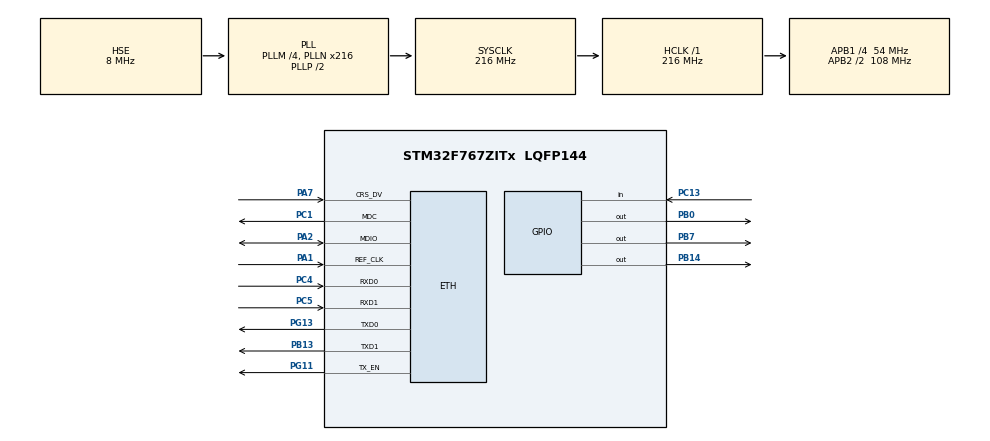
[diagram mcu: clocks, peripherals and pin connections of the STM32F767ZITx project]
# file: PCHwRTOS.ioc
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CORTEX_M7.ART_ACCLERATOR_ENABLE=0
CORTEX_M7.CPU_ICache=Disabled
CORTEX_M7.PREFETCH_ENABLE=0
ETH.MACAddr=44\:84\:23\:84\:44\:77
ETH.MediaInterface=ETH_MEDIA_INTERFACE_RMII
ETH.PHY_BCR=0x00
ETH.PhyAddress=0
LWIP.GATEWAY_ADDRESS=192.168.000.001
LWIP.IP_ADDRESS=192.168.000.211
LWIP.LWIP_DHCP=1
LWIP.LWIP_DNS=1
LWIP.NETMASK_ADDRESS=255.255.255.000
LWIP.Version=v2.0.0_Cube
Mcu.Family=STM32F7
Mcu.Name=STM32F767ZITx
Mcu.Package=LQFP144
NVIC.PriorityGroup=NVIC_PRIORITYGROUP_4
PA1.GPIO_PuPd=GPIO_PULLUP
PA1.Mode=RMII
PA1.Signal=ETH_REF_CLK
PA13.Mode=Serial_Wire
PA13.Signal=SYS_JTMS-SWDIO
PA14.Mode=Serial_Wire
PA14.Signal=SYS_JTCK-SWCLK
PA2.GPIO_PuPd=GPIO_PULLUP
PA2.Mode=RMII
PA2.Signal=ETH_MDIO
PA7.GPIO_PuPd=GPIO_PULLUP
PA7.Mode=RMII
PA7.Signal=ETH_CRS_DV
PB0.Signal=GPIO_Output
PB13.GPIO_PuPd=GPIO_PULLUP
PB13.Mode=RMII
PB13.Signal=ETH_TXD1
PB14.Signal=GPIO_Output
PB7.Signal=GPIO_Output
PC1.GPIO_PuPd=GPIO_PULLUP
PC1.Mode=RMII
PC1.Signal=ETH_MDC
PC13.Signal=GPIO_Input
PC4.GPIO_PuPd=GPIO_PULLUP
PC4.Mode=RMII
PC4.Signal=ETH_RXD0
PC5.GPIO_PuPd=GPIO_PULLUP
PC5.Mode=RMII
PC5.Signal=ETH_RXD1
PG11.GPIO_PuPd=GPIO_PULLUP
PG11.Mode=RMII
PG11.Signal=ETH_TX_EN
PG13.GPIO_PuPd=GPIO_PULLUP
PG13.Mode=RMII
PG13.Signal=ETH_TXD0
PH0/OSC_IN.Mode=HSE-External-Clock-Source
PH0/OSC_IN.Signal=RCC_OSC_IN
PH1/OSC_OUT.Mode=HSE-External-Clock-Source
PH1/OSC_OUT.Signal=RCC_OSC_OUT
ProjectManager.HeapSize=0x2000
ProjectManager.StackSize=0x4000
ProjectManager.TargetToolchain=MDK-ARM V5
RCC.48MHZClocksFreq_Value=24000000
RCC.AHBFreq_Value=216000000
RCC.APB1CLKDivider=RCC_HCLK_DIV4
RCC.APB1Freq_Value=54000000
RCC.APB1TimFreq_Value=108000000
RCC.APB2CLKDivider=RCC_HCLK_DIV2
RCC.APB2Freq_Value=108000000
RCC.APB2TimFreq_Value=216000000
RCC.CortexFreq_Value=216000000
RCC.HCLKFreq_Value=216000000
RCC.HSE_VALUE=8000000
RCC.HSI_VALUE=16000000
RCC.LSE_VALUE=32768
RCC.PLLM=4
RCC.PLLMUL=RCC_PLL_MUL9
RCC.PLLN=216
RCC.PLLSourceVirtual=RCC_PLLSOURCE_HSE
RCC.PRESCALERUSB=RCC_USBCLKSOURCE_PLL_DIV1_5
RCC.SYSCLKFreq_VALUE=216000000
RCC.SYSCLKSource=RCC_SYSCLKSOURCE_PLLCLK
RCC.SYSCLKSourceVirtual=RCC_SYSCLKSOURCE_PLLCLK
RCC.USBFreq_Value=216000000
RCC.VCOOutputFreq_Value=432000000
VP_LWIP_VS_Enabled.Mode=Enabled
board=NUCLEO-F767ZI

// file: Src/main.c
/**
  ******************************************************************************
  * File Name          : main.c
  * Description        : Main program body
  ******************************************************************************
  * This notice applies to any and all portions of this file
  * that are not between comment pairs USER CODE BEGIN and
  * USER CODE END. Other portions of this file, whether
  * inserted by the user or by software development tools
  * are owned by their respective copyright owners.
  *
  * Copyright (c) 2018 STMicroelectronics International N.V.
  * All rights reserved.
  *
  * Redistribution and use in source and binary forms, with or without
  * modification, are permitted, provided that the following conditions are met:
  *
  * 1. Redistribution of source code must retain the above copyright notice,
  *    this list of conditions and the following disclaimer.
  * 2. Redistributions in binary form must reproduce the above copyright notice,
  *    this list of conditions and the following disclaimer in the documentation
  *    and/or other materials provided with the distribution.
  * 3. Neither the name of STMicroelectronics nor the names of other
  *    contributors to this software may be used to endorse or promote products
  *    derived from this software without specific written permission.
  * 4. This software, including modifications and/or derivative works of this
  *    software, must execute solely and exclusively on microcontroller or
  *    microprocessor devices manufactured by or for STMicroelectronics.
  * 5. Redistribution and use of this software other than as permitted under
  *    this license is void and will automatically terminate your rights under
  *    this license.
  *
  * THIS SOFTWARE IS PROVIDED BY STMICROELECTRONICS AND CONTRIBUTORS "AS IS"
  * AND ANY EXPRESS, IMPLIED OR STATUTORY WARRANTIES, INCLUDING, BUT NOT
  * LIMITED TO, THE IMPLIED WARRANTIES OF MERCHANTABILITY, FITNESS FOR A
  * PARTICULAR PURPOSE AND NON-INFRINGEMENT OF THIRD PARTY INTELLECTUAL PROPERTY
  * RIGHTS ARE DISCLAIMED TO THE FULLEST EXTENT PERMITTED BY LAW. IN NO EVENT
  * SHALL STMICROELECTRONICS OR CONTRIBUTORS BE LIABLE FOR ANY DIRECT, INDIRECT,
  * INCIDENTAL, SPECIAL, EXEMPLARY, OR CONSEQUENTIAL DAMAGES (INCLUDING, BUT NOT
  * LIMITED TO, PROCUREMENT OF SUBSTITUTE GOODS OR SERVICES; LOSS OF USE, DATA,
  * OR PROFITS; OR BUSINESS INTERRUPTION) HOWEVER CAUSED AND ON ANY THEORY OF
  * LIABILITY, WHETHER IN CONTRACT, STRICT LIABILITY, OR TORT (INCLUDING
  * NEGLIGENCE OR OTHERWISE) ARISING IN ANY WAY OUT OF THE USE OF THIS SOFTWARE,
  * EVEN IF ADVISED OF THE POSSIBILITY OF SUCH DAMAGE.
  *
  ******************************************************************************
  */

#include "main.h"
#include "stm32f7xx_hal.h"
#include "lwip.h"

/* USER CODE BEGIN Includes */
#include "net.h"
/* USER CODE END Includes */

/* USER CODE BEGIN PV */
/* Private variables ---------------------------------------------------------*/

/* USER CODE END PV */

void SystemClock_Config(void);
static void MX_GPIO_Init(void);

/* USER CODE BEGIN PFP */
/* Private function prototypes -----------------------------------------------*/

/* USER CODE END PFP */

/* USER CODE BEGIN 0 */
extern struct netif gnetif;
/* USER CODE END 0 */

int main(void)
{

  /* MCU Configuration----------------------------------------------------------*/

  /* Reset of all peripherals, Initializes the Flash interface and the Systick. */
  HAL_Init();

  /* Configure the system clock */
  SystemClock_Config();

  /* Initialize all configured peripherals */
  MX_GPIO_Init();
  MX_LWIP_Init();

  /* USER CODE BEGIN 2 */
  echo_init();
  /* USER CODE END 2 */

  /* Infinite loop */
  while (1)
  {

  /* USER CODE BEGIN 3 */
  ethernetif_input(&gnetif);
  sys_check_timeouts();
  }
  /* USER CODE END 3 */

}

/** System Clock Configuration
*/
void SystemClock_Config(void)
{

  RCC_OscInitTypeDef RCC_OscInitStruct;
  RCC_ClkInitTypeDef RCC_ClkInitStruct;

    /**Configure the main internal regulator output voltage
    */
  __HAL_RCC_PWR_CLK_ENABLE();

  __HAL_PWR_VOLTAGESCALING_CONFIG(PWR_REGULATOR_VOLTAGE_SCALE1);

    /**Initializes the CPU, AHB and APB busses clocks
    */
  RCC_OscInitStruct.OscillatorType = RCC_OSCILLATORTYPE_HSE;
  RCC_OscInitStruct.HSEState = RCC_HSE_BYPASS;
  RCC_OscInitStruct.PLL.PLLState = RCC_PLL_ON;
  RCC_OscInitStruct.PLL.PLLSource = RCC_PLLSOURCE_HSE;
  RCC_OscInitStruct.PLL.PLLM = 4;
  RCC_OscInitStruct.PLL.PLLN = 216;
  RCC_OscInitStruct.PLL.PLLP = RCC_PLLP_DIV2;
  RCC_OscInitStruct.PLL.PLLQ = 2;
  if (HAL_RCC_OscConfig(&RCC_OscInitStruct) != HAL_OK)
  {
    _Error_Handler(__FILE__, __LINE__);
  }

    /**Activate the Over-Drive mode
    */
  if (HAL_PWREx_EnableOverDrive() != HAL_OK)
  {
    _Error_Handler(__FILE__, __LINE__);
  }

    /**Initializes the CPU, AHB and APB busses clocks
    */
  RCC_ClkInitStruct.ClockType = RCC_CLOCKTYPE_HCLK|RCC_CLOCKTYPE_SYSCLK
                              |RCC_CLOCKTYPE_PCLK1|RCC_CLOCKTYPE_PCLK2;
  RCC_ClkInitStruct.SYSCLKSource = RCC_SYSCLKSOURCE_PLLCLK;
  RCC_ClkInitStruct.AHBCLKDivider = RCC_SYSCLK_DIV1;
  RCC_ClkInitStruct.APB1CLKDivider = RCC_HCLK_DIV4;
  RCC_ClkInitStruct.APB2CLKDivider = RCC_HCLK_DIV2;

  if (HAL_RCC_ClockConfig(&RCC_ClkInitStruct, FLASH_LATENCY_7) != HAL_OK)
  {
    _Error_Handler(__FILE__, __LINE__);
  }

    /**Configure the Systick interrupt time
    */
  HAL_SYSTICK_Config(HAL_RCC_GetHCLKFreq()/1000);

    /**Configure the Systick
    */
  HAL_SYSTICK_CLKSourceConfig(SYSTICK_CLKSOURCE_HCLK);

  /* SysTick_IRQn interrupt configuration */
  HAL_NVIC_SetPriority(SysTick_IRQn, 0, 0);
}

/** Configure pins as
        * Analog
        * Input
        * Output
        * EVENT_OUT
        * EXTI
        * Free pins are configured automatically as Analog (this feature is enabled through
        * the Code Generation settings)
*/
static void MX_GPIO_Init(void)
{

  GPIO_InitTypeDef GPIO_InitStruct;

  /* GPIO Ports Clock Enable */
  __HAL_RCC_GPIOE_CLK_ENABLE();
  __HAL_RCC_GPIOC_CLK_ENABLE();
  __HAL_RCC_GPIOF_CLK_ENABLE();
  __HAL_RCC_GPIOH_CLK_ENABLE();
  __HAL_RCC_GPIOA_CLK_ENABLE();
  __HAL_RCC_GPIOB_CLK_ENABLE();
  __HAL_RCC_GPIOG_CLK_ENABLE();
  __HAL_RCC_GPIOD_CLK_ENABLE();

  /*Configure GPIO pin Output Level */
  HAL_GPIO_WritePin(GPIOB, GPIO_PIN_0|GPIO_PIN_14|GPIO_PIN_7, GPIO_PIN_RESET);

  /*Configure GPIO pins : PE2 PE3 PE4 PE5
                           PE6 PE7 PE8 PE9
                           PE10 PE11 PE12 PE13
                           PE14 PE15 PE0 PE1 */
  GPIO_InitStruct.Pin = GPIO_PIN_2|GPIO_PIN_3|GPIO_PIN_4|GPIO_PIN_5
                          |GPIO_PIN_6|GPIO_PIN_7|GPIO_PIN_8|GPIO_PIN_9
                          |GPIO_PIN_10|GPIO_PIN_11|GPIO_PIN_12|GPIO_PIN_13
                          |GPIO_PIN_14|GPIO_PIN_15|GPIO_PIN_0|GPIO_PIN_1;
  GPIO_InitStruct.Mode = GPIO_MODE_ANALOG;
  GPIO_InitStruct.Pull = GPIO_NOPULL;
  HAL_GPIO_Init(GPIOE, &GPIO_InitStruct);

  /*Configure GPIO pin : PC13 */
  GPIO_InitStruct.Pin = GPIO_PIN_13;
  GPIO_InitStruct.Mode = GPIO_MODE_INPUT;
  GPIO_InitStruct.Pull = GPIO_NOPULL;
  HAL_GPIO_Init(GPIOC, &GPIO_InitStruct);

  /*Configure GPIO pins : PC14 PC15 PC0 PC2
                           PC3 PC6 PC7 PC8
                           PC9 PC10 PC11 PC12 */
  GPIO_InitStruct.Pin = GPIO_PIN_14|GPIO_PIN_15|GPIO_PIN_0|GPIO_PIN_2
                          |GPIO_PIN_3|GPIO_PIN_6|GPIO_PIN_7|GPIO_PIN_8
                          |GPIO_PIN_9|GPIO_PIN_10|GPIO_PIN_11|GPIO_PIN_12;
  GPIO_InitStruct.Mode = GPIO_MODE_ANALOG;
  GPIO_InitStruct.Pull = GPIO_NOPULL;
  HAL_GPIO_Init(GPIOC, &GPIO_InitStruct);

  /*Configure GPIO pins : PF0 PF1 PF2 PF3
                           PF4 PF5 PF6 PF7
                           PF8 PF9 PF10 PF11
                           PF12 PF13 PF14 PF15 */
  GPIO_InitStruct.Pin = GPIO_PIN_0|GPIO_PIN_1|GPIO_PIN_2|GPIO_PIN_3
                          |GPIO_PIN_4|GPIO_PIN_5|GPIO_PIN_6|GPIO_PIN_7
                          |GPIO_PIN_8|GPIO_PIN_9|GPIO_PIN_10|GPIO_PIN_11
                          |GPIO_PIN_12|GPIO_PIN_13|GPIO_PIN_14|GPIO_PIN_15;
  GPIO_InitStruct.Mode = GPIO_MODE_ANALOG;
  GPIO_InitStruct.Pull = GPIO_NOPULL;
  HAL_GPIO_Init(GPIOF, &GPIO_InitStruct);

  /*Configure GPIO pins : PA0 PA3 PA4 PA5
                           PA6 PA8 PA9 PA10
                           PA11 PA12 PA15 */
  GPIO_InitStruct.Pin = GPIO_PIN_0|GPIO_PIN_3|GPIO_PIN_4|GPIO_PIN_5
                          |GPIO_PIN_6|GPIO_PIN_8|GPIO_PIN_9|GPIO_PIN_10
                          |GPIO_PIN_11|GPIO_PIN_12|GPIO_PIN_15;
  GPIO_InitStruct.Mode = GPIO_MODE_ANALOG;
  GPIO_InitStruct.Pull = GPIO_NOPULL;
  HAL_GPIO_Init(GPIOA, &GPIO_InitStruct);

  /*Configure GPIO pins : PB0 PB14 PB7 */
  GPIO_InitStruct.Pin = GPIO_PIN_0|GPIO_PIN_14|GPIO_PIN_7;
  GPIO_InitStruct.Mode = GPIO_MODE_OUTPUT_PP;
  GPIO_InitStruct.Pull = GPIO_NOPULL;
  GPIO_InitStruct.Speed = GPIO_SPEED_FREQ_LOW;
  HAL_GPIO_Init(GPIOB, &GPIO_InitStruct);

  /*Configure GPIO pins : PB1 PB2 PB10 PB11
                           PB12 PB15 PB3 PB4
                           PB5 PB6 PB8 PB9 */
  GPIO_InitStruct.Pin = GPIO_PIN_1|GPIO_PIN_2|GPIO_PIN_10|GPIO_PIN_11
                          |GPIO_PIN_12|GPIO_PIN_15|GPIO_PIN_3|GPIO_PIN_4
                          |GPIO_PIN_5|GPIO_PIN_6|GPIO_PIN_8|GPIO_PIN_9;
  GPIO_InitStruct.Mode = GPIO_MODE_ANALOG;
  GPIO_InitStruct.Pull = GPIO_NOPULL;
  HAL_GPIO_Init(GPIOB, &GPIO_InitStruct);

  /*Configure GPIO pins : PG0 PG1 PG2 PG3
                           PG4 PG5 PG6 PG7
                           PG8 PG9 PG10 PG12
                           PG14 PG15 */
  GPIO_InitStruct.Pin = GPIO_PIN_0|GPIO_PIN_1|GPIO_PIN_2|GPIO_PIN_3
                          |GPIO_PIN_4|GPIO_PIN_5|GPIO_PIN_6|GPIO_PIN_7
                          |GPIO_PIN_8|GPIO_PIN_9|GPIO_PIN_10|GPIO_PIN_12
                          |GPIO_PIN_14|GPIO_PIN_15;
  GPIO_InitStruct.Mode = GPIO_MODE_ANALOG;
  GPIO_InitStruct.Pull = GPIO_NOPULL;
  HAL_GPIO_Init(GPIOG, &GPIO_InitStruct);

  /*Configure GPIO pins : PD8 PD9 PD10 PD11
                           PD12 PD13 PD14 PD15
                           PD0 PD1 PD2 PD3
                           PD4 PD5 PD6 PD7 */
  GPIO_InitStruct.Pin = GPIO_PIN_8|GPIO_PIN_9|GPIO_PIN_10|GPIO_PIN_11
                          |GPIO_PIN_12|GPIO_PIN_13|GPIO_PIN_14|GPIO_PIN_15
                          |GPIO_PIN_0|GPIO_PIN_1|GPIO_PIN_2|GPIO_PIN_3
                          |GPIO_PIN_4|GPIO_PIN_5|GPIO_PIN_6|GPIO_PIN_7;
  GPIO_InitStruct.Mode = GPIO_MODE_ANALOG;
  GPIO_InitStruct.Pull = GPIO_NOPULL;
  HAL_GPIO_Init(GPIOD, &GPIO_InitStruct);

}

void _Error_Handler(char * file, int line)
{
  while(1)
  {
  }
}

/************************ (C) COPYRIGHT STMicroelectronics *****END OF FILE****/
